# CW32L010 register map
Vendor: Wuhan Xinyuan Semiconductor Co.Ltd; Series: ARMCM0P; File version: 1.2
CPU: CM0+ r0p1, little endian, no MPU, no FPU, 2 interrupt priority bits
Registers are 32-bit, read-write, no defined reset value unless marked. A register's access mark holds for its fields unless they carry their own. Offsets are from the block's base; [hi:lo] are bit positions; {n}, {i} and the like mark numbered series; 'fields as' and 'values as' point back to an identical list.

## I2C1
Base 0x40005800
0x00 BRREN
  [0] EN
0x04 BRR
  [7:0] BRR
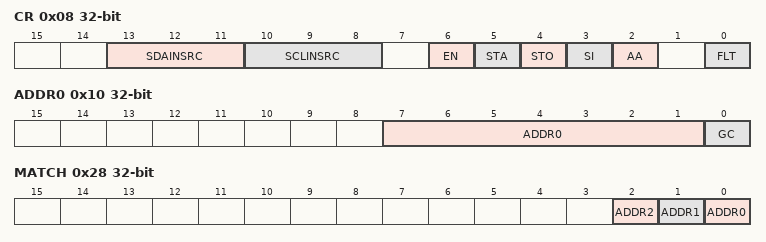
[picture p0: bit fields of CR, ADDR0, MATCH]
0x08 CR — Control register
  [13:11] SDAINSRC, [10:8] SCLINSRC, [6] EN, [5] STA, [4] STO, [3] SI, [2] AA, [0] FLT
0x0C DR — Data register
  [7:0] DR
0x10 ADDR0 — Slave Addrress0
  [7:1] ADDR0, [0] GC
0x14 STAT ro — Status register
  [7:0] STAT
0x20 ADDR1 — Slave Addrress1
  [7:1] ADDR1
0x24 ADDR2 — Slave Addrress2
  [7:1] ADDR2
0x28 MATCH ro — Slave Addrress match flag
  [2] ADDR2, [1] ADDR1, [0] ADDR0

## IRMOD
Base 0x40004080
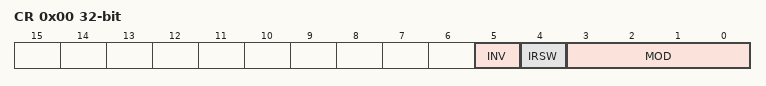
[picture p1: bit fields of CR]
0x00 CR — Input selection register
  [5] INV, [4] IRSW, [3:0] MOD

## IWDT
Base 0x40005000
0x00 KR wo — Key register
  [15:0] KR
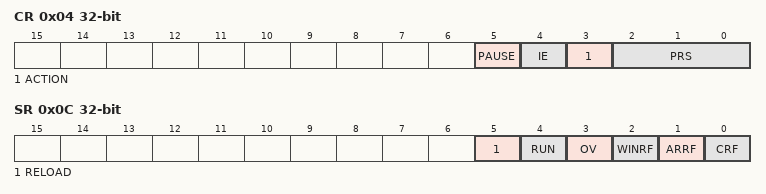
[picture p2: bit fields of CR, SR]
0x04 CR — Control register
  [5] PAUSE, [4] IE, [3] ACTION, [2:0] PRS
0x08 ARR — Auto reload register
  [11:0] ARR
0x0C SR — Status register
  [5] RELOAD ro, [4] RUN ro, [3] OV, [2] WINRF ro, [1] ARRF ro, [0] CRF ro
0x10 WINR — Window register
  [11:0] WINR
0x24 CNT ro — counter
  [11:0] CNT

## LPTIM
Base 0x40006000
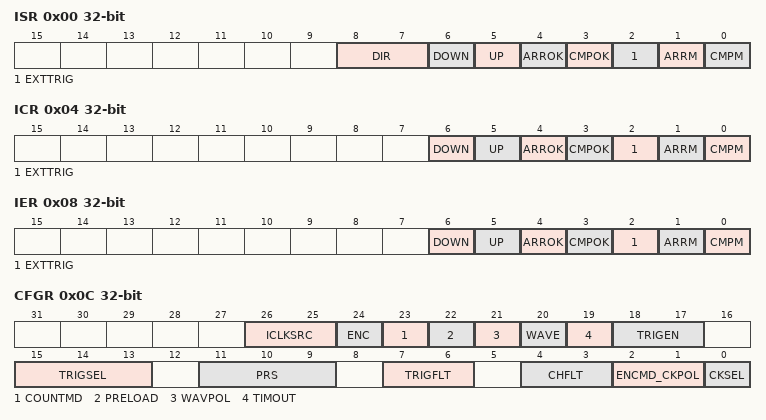
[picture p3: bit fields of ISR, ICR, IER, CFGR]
0x00 ISR ro
  [8:7] DIR, [6] DOWN, [5] UP, [4] ARROK, [3] CMPOK, [2] EXTTRIG, [1] ARRM, [0] CMPM
0x04 ICR
  [6] DOWN, [5] UP, [4] ARROK, [3] CMPOK, [2] EXTTRIG, [1] ARRM, [0] CMPM
0x08 IER
  fields as ICR
0x0C CFGR
  [26:25] ICLKSRC, [24] ENC, [23] COUNTMD, [22] PRELOAD, [21] WAVPOL, [20] WAVE, [19] TIMOUT, [18:17] TRIGEN, [15:13] TRIGSEL, [11:9] PRS, [7:6] TRIGFLT, [4:3] CHFLT, [2:1] ENCMD_CKPOL, [0] CKSEL
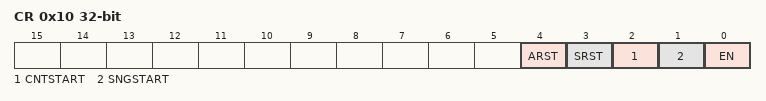
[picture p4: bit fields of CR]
0x10 CR
  [4] ARST, [3] SRST, [2] CNTSTART, [1] SNGSTART, [0] EN
0x14 CMP
  [15:0] CMP
0x18 ARR
  [15:0] ARR
0x1C CNT ro
  [15:0] CNT

## RAM
Base 0x40022400
0x00 IER
  [0] PARITY
0x04 ADDR ro
  [31:0] ADDR rw
0x08 ISR ro
  [0] PARITY
0x0C ICR
  [0] PARITY

## UART1
Base 0x40000C00
Same registers: UART2 0x40001000
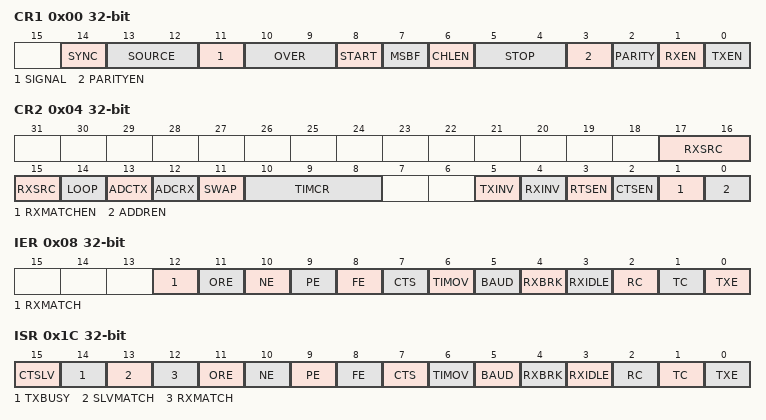
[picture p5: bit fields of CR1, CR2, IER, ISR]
0x00 CR1 — Control register1
  [14] SYNC, [13:12] SOURCE, [11] SIGNAL, [10:9] OVER, [8] START, [7] MSBF, [6] CHLEN, [5:4] STOP, [3] PARITYEN, [2] PARITY, [1] RXEN, [0] TXEN
0x04 CR2 — Control register2
  [17:15] RXSRC, [14] LOOP, [13] ADCTX, [12] ADCRX, [11] SWAP, [10:8] TIMCR, [5] TXINV, [4] RXINV, [3] RTSEN, [2] CTSEN, [1] RXMATCHEN, [0] ADDREN
0x08 IER — Interrupt enable register
  [12] RXMATCH, [11] ORE, [10] NE, [9] PE, [8] FE, [7] CTS, [6] TIMOV, [5] BAUD, [4] RXBRK, [3] RXIDLE, [2] RC, [1] TC, [0] TXE
0x0C BRRI
  [15:0] BRRI
0x10 BRRF
  [3:0] BRRF
0x14 TIMARR
  [23:0] TIMARR
0x18 TIMCNT ro
  [23:0] TIMCNT
0x1C ISR ro — Interrupt status register
  [15] CTSLV, [14] TXBUSY, [13] SLVMATCH, [12] RXMATCH, [11] ORE, [10] NE, [9] PE, [8] FE, [7] CTS, [6] TIMOV, [5] BAUD, [4] RXBRK, [3] RXIDLE, [2] RC, [1] TC, [0] TXE
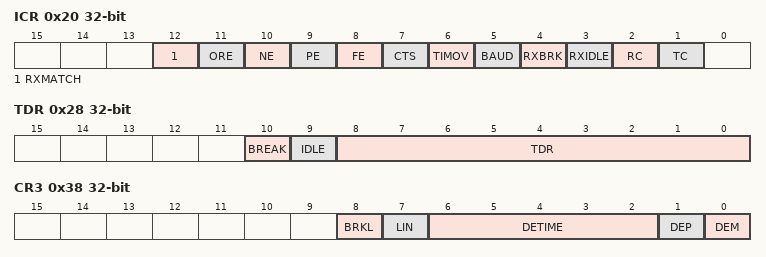
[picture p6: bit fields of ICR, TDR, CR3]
0x20 ICR — Interrupt flag clear register
  [12] RXMATCH, [11] ORE, [10] NE, [9] PE, [8] FE, [7] CTS, [6] TIMOV, [5] BAUD, [4] RXBRK, [3] RXIDLE, [2] RC, [1] TC
0x24 RDR ro — Data reg for read
  [8:0] RDR
0x28 TDR wo — Data reg for write
  [10] BREAK, [9] IDLE, [8:0] TDR
0x30 ADDR — Slave addr
  [7:0] ADDR
0x34 MASK — Slave addr mask
  [7:0] MASK
0x38 CR3 — Control register3
  [8] BRKL, [7] LIN, [6:2] DETIME, [1] DEP, [0] DEM
0x3C RXMATCH
  [8:0] RXMATCH

## LVD
Base 0x400000D0
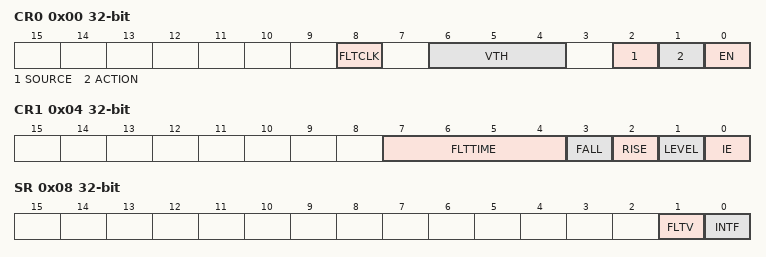
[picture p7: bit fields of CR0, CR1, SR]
0x00 CR0 — Control register0
  [8] FLTCLK, [6:4] VTH, [2] SOURCE, [1] ACTION, [0] EN
0x04 CR1 — Control register1
  [7:4] FLTTIME, [3] FALL, [2] RISE, [1] LEVEL, [0] IE
0x08 SR — status register
  [1] FLTV ro, [0] INTF

## RTC
Base 0x40004400
0x00 KEY wo
  [7:0] KEY
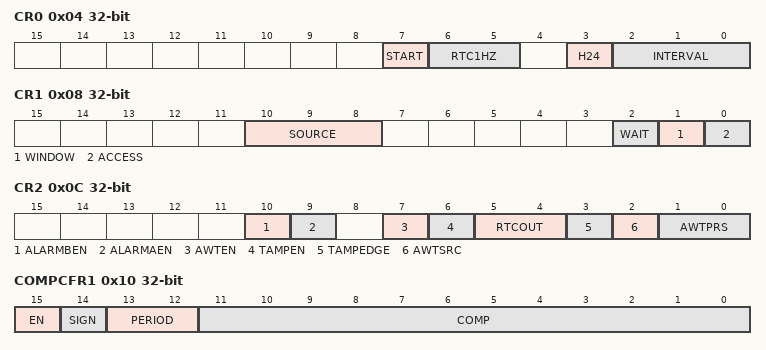
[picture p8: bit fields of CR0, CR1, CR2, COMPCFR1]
0x04 CR0
  [7] START, [6:5] RTC1HZ, [3] H24, [2:0] INTERVAL
0x08 CR1
  [10:8] SOURCE, [2] WAIT ro, [1] WINDOW ro, [0] ACCESS
0x0C CR2
  [10] ALARMBEN, [9] ALARMAEN, [7] AWTEN, [6] TAMPEN, [5:4] RTCOUT, [3] TAMPEDGE, [2] AWTSRC, [1:0] AWTPRS
0x10 COMPCFR1
  [15] EN, [14] SIGN, [13:12] PERIOD, [11:0] COMP
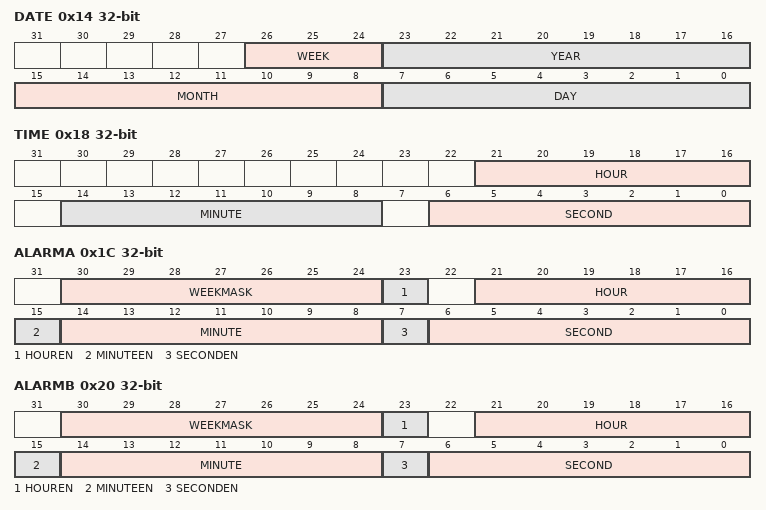
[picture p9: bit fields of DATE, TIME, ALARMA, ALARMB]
0x14 DATE
  [26:24] WEEK, [23:16] YEAR, [15:8] MONTH, [7:0] DAY
0x18 TIME
  [21:16] HOUR, [14:8] MINUTE, [6:0] SECOND
0x1C ALARMA
  [30:24] WEEKMASK, [23] HOUREN, [21:16] HOUR, [15] MINUTEEN, [14:8] MINUTE, [7] SECONDEN, [6:0] SECOND
0x20 ALARMB
  fields as ALARMA
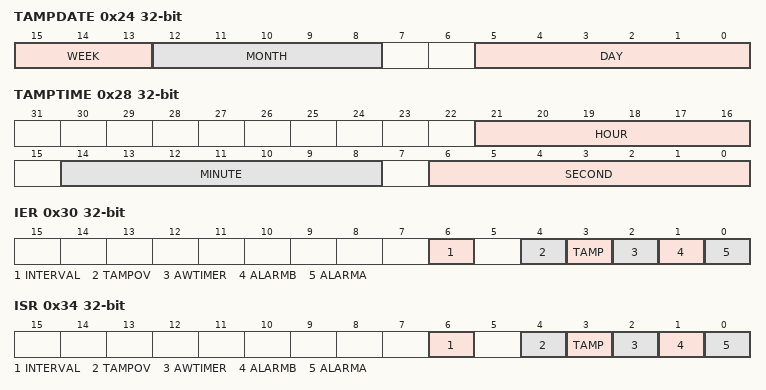
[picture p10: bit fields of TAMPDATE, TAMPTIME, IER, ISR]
0x24 TAMPDATE ro
  [15:13] WEEK, [12:8] MONTH, [5:0] DAY
0x28 TAMPTIME ro
  [21:16] HOUR, [14:8] MINUTE, [6:0] SECOND
0x2C AWTARR
  [15:0] ARR
0x30 IER
  [6] INTERVAL, [4] TAMPOV, [3] TAMP, [2] AWTIMER, [1] ALARMB, [0] ALARMA
0x34 ISR ro
  fields as IER
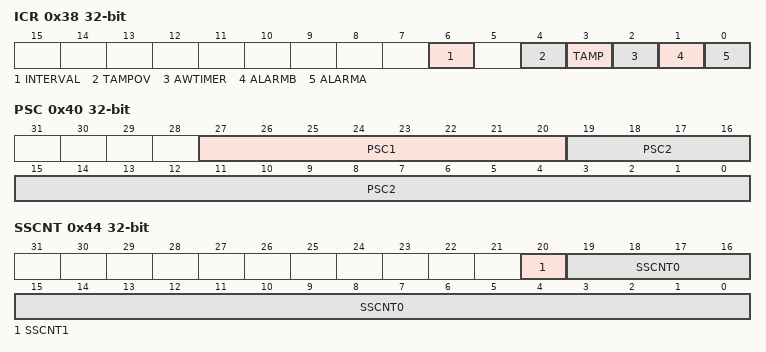
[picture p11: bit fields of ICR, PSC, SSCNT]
0x38 ICR
  fields as IER
0x3C AWTCNT ro
  [15:0] CNT
0x40 PSC
  [27:20] PSC1, [19:0] PSC2
0x44 SSCNT ro
  [20] SSCNT1, [19:0] SSCNT0

## SPI
Base 0x40000800
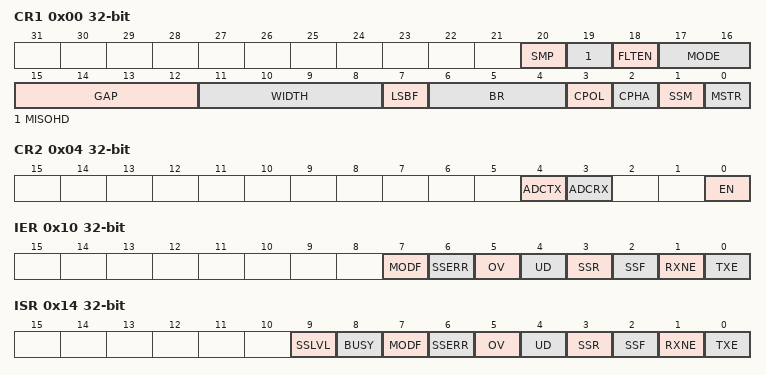
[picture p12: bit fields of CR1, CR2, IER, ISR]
0x00 CR1 — Control register1
  [20] SMP, [19] MISOHD, [18] FLTEN, [17:16] MODE, [15:12] GAP, [11:8] WIDTH, [7] LSBF, [6:4] BR, [3] CPOL, [2] CPHA, [1] SSM, [0] MSTR
0x04 CR2 — Control register2
  [4] ADCTX, [3] ADCRX, [0] EN
0x08 CR3
  [0] HDOE
0x0C SSI — Slave slect register
  [0] SSI
0x10 IER — Interrupt enable register
  [7] MODF, [6] SSERR, [5] OV, [4] UD, [3] SSR, [2] SSF, [1] RXNE, [0] TXE
0x14 ISR ro — Interrupt status register
  [9] SSLVL, [8] BUSY, [7] MODF, [6] SSERR, [5] OV, [4] UD, [3] SSR, [2] SSF, [1] RXNE, [0] TXE
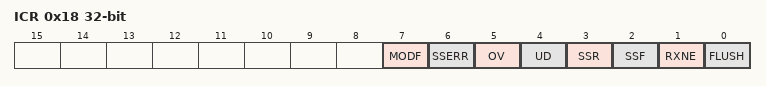
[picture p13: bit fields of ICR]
0x18 ICR — Interrupt flag clear register
  [7] MODF, [6] SSERR, [5] OV, [4] UD, [3] SSR, [2] SSF, [1] RXNE, [0] FLUSH
0x1C DR — Data register
  [15:0] DR

## SYSCTRL — System Ctrl
Base 0x40004000
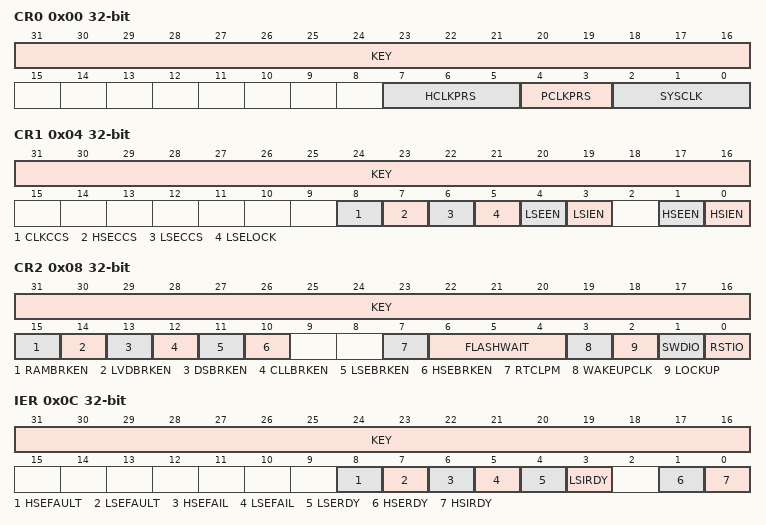
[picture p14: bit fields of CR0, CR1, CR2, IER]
0x00 CR0 — Control Reg0
  [31:16] KEY wo, [7:5] HCLKPRS, [4:3] PCLKPRS, [2:0] SYSCLK
0x04 CR1 — Control Reg1
  [31:16] KEY wo, [8] CLKCCS, [7] HSECCS, [6] LSECCS, [5] LSELOCK, [4] LSEEN, [3] LSIEN, [1] HSEEN, [0] HSIEN
0x08 CR2 — Control Reg2
  [31:16] KEY wo, [15] RAMBRKEN, [14] LVDBRKEN, [13] DSBRKEN, [12] CLLBRKEN, [11] LSEBRKEN, [10] HSEBRKEN, [7] RTCLPM, [6:4] FLASHWAIT, [3] WAKEUPCLK, [2] LOCKUP, [1] SWDIO, [0] RSTIO
0x0C IER — Interupt Enable Reg
  [31:16] KEY wo, [8] HSEFAULT, [7] LSEFAULT, [6] HSEFAIL, [5] LSEFAIL, [4] LSERDY, [3] LSIRDY, [1] HSERDY, [0] HSIRDY
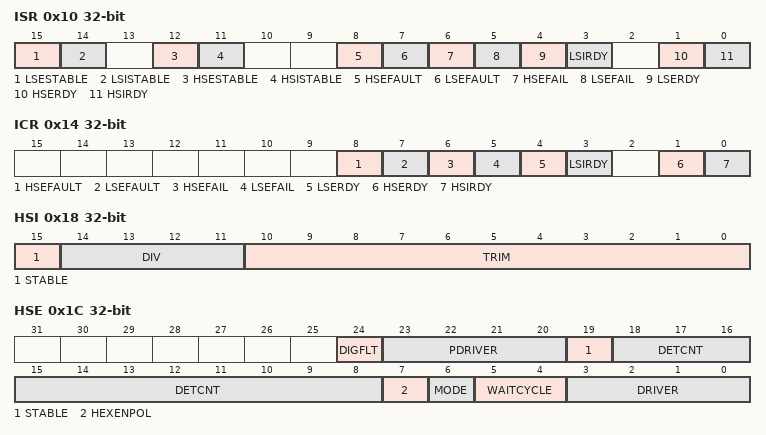
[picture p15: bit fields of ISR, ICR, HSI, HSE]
0x10 ISR ro — Interupt Status Reg
  [15] LSESTABLE, [14] LSISTABLE, [12] HSESTABLE, [11] HSISTABLE, [8] HSEFAULT, [7] LSEFAULT, [6] HSEFAIL, [5] LSEFAIL, [4] LSERDY, [3] LSIRDY, [1] HSERDY, [0] HSIRDY
0x14 ICR — Interupt Clear Reg
  [8] HSEFAULT, [7] LSEFAULT, [6] HSEFAIL, [5] LSEFAIL, [4] LSERDY, [3] LSIRDY, [1] HSERDY, [0] HSIRDY
0x18 HSI — HSI Control Reg
  [15] STABLE ro, [14:11] DIV, [10:0] TRIM
0x1C HSE — HEX Control Reg
  [24] DIGFLT, [23:20] PDRIVER, [19] STABLE ro, [18:8] DETCNT, [7] HEXENPOL, [6] MODE, [5:4] WAITCYCLE, [3:0] DRIVER
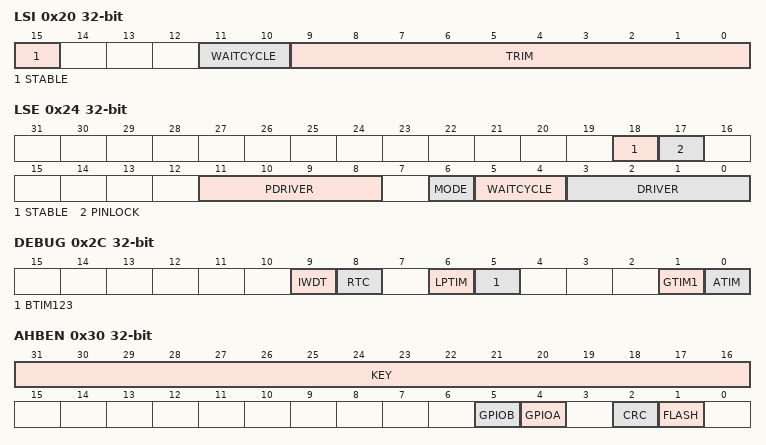
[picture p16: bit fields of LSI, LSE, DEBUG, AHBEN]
0x20 LSI — LSI Control Reg
  [15] STABLE ro, [11:10] WAITCYCLE, [9:0] TRIM
0x24 LSE — LSE Control Reg
  [18] STABLE ro, [17] PINLOCK, [11:8] PDRIVER, [6] MODE, [5:4] WAITCYCLE, [3:0] DRIVER
0x2C DEBUG — Debug Control Reg
  [9] IWDT, [8] RTC, [6] LPTIM, [5] BTIM123, [1] GTIM1, [0] ATIM
0x30 AHBEN — AHB Clock Control Reg
  [31:16] KEY, [5] GPIOB, [4] GPIOA, [2] CRC, [1] FLASH
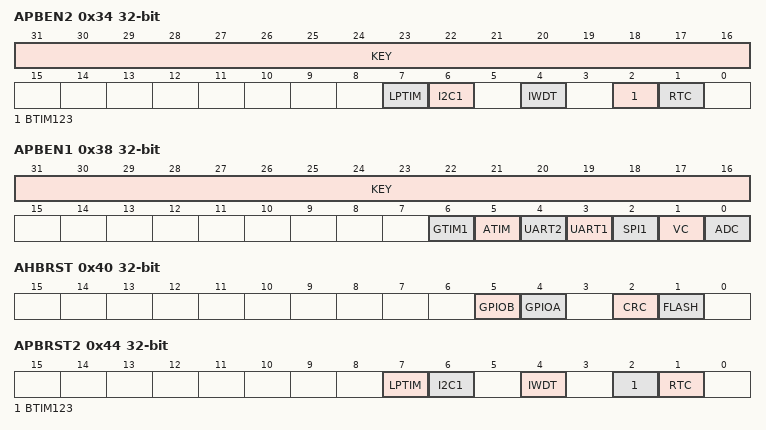
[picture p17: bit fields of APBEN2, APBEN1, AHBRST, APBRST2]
0x34 APBEN2 — APB Clock Control Reg2
  [31:16] KEY wo, [7] LPTIM, [6] I2C1, [4] IWDT, [2] BTIM123, [1] RTC
0x38 APBEN1 — APB Clock Control Reg1
  [31:16] KEY wo, [6] GTIM1, [5] ATIM, [4] UART2, [3] UART1, [2] SPI1, [1] VC, [0] ADC
0x40 AHBRST — AHB Reset Control Reg
  [5] GPIOB, [4] GPIOA, [2] CRC, [1] FLASH
0x44 APBRST2 — APB Reset Control Reg2
  [7] LPTIM, [6] I2C1, [4] IWDT, [2] BTIM123, [1] RTC
0x48 APBRST1 — APB Reset Control Reg1
  [6] GTIM1, [5] ATIM, [4] UART2, [3] UART1, [2] SPI1, [1] VC, [0] ADC
0x4C RESETFLAG — Reset Status Reg
  [9] SYSRESETREQ, [8] LOCKUP, [6] RSTB, [4] IWDT, [3] LVD, [0] POR
0x70 MCO — Master Clock Output Control Reg
  [6:4] DIV, [3:0] SOURCE

## VC1
Base 0x400000A4
Same registers: VC2 0x400000B4
0x00 CR0 — VC Control register0
  [9:8] INN — desc NCHANNEL
  [7:6] INP — desc PCHANNEL
  [5] WINDOW
  [4] POL
  [3] IE
  [2] HYS
  [1] RESP
  [0] EN
0x04 CR1 — VC Control register1
  [17] BLANKLVL, [16:14] BLANKTIME, [n+7] BLANKATCH{n} (n=1..6), [7] HIGHIE, [6] RISEIE, [5] FALLIE, [4] FLTCLK, [3:0] FLTTIME
0x08 SR — VC State REG
  [1] FLTV ro, [0] INTF

## VCDIV
Base 0x400000A0
0x00 DIV — VCREF Control register
  [5] VIN, [4] EN, [2:0] DIV
